# ATmega4809 device description
Architecture: AVR8X; Family: AVR MEGA
Registers are 8-bit, read-write, no defined reset value unless marked. A register's access mark holds for its fields unless they carry their own. Offsets are from the block's base; [hi:lo] are bit positions; {n}, {i} and the like mark numbered series; 'fields as' and 'values as' point back to an identical list.

## FUSE — Fuses
Instances: FUSE 0x1280
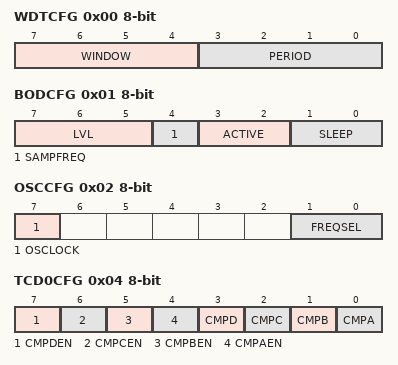
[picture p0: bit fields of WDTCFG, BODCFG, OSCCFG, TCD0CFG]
0x00 WDTCFG — Watchdog Configuration
  [7:4] WINDOW — Watchdog Window Timeout Period
    0=OFF; 1=8CLK (8 cycles (8ms)); 2=16CLK (16 cycles (16ms)); 3=32CLK (32 cycles (32ms)); 4=64CLK (64 cycles (64ms)); 5=128CLK (128 cycles (0.128s)); 6=256CLK (256 cycles (0.256s)); 7=512CLK (512 cycles (0.512s)); 8=1KCLK (1K cycles (1.0s)); 9=2KCLK (2K cycles (2.0s)); 10=4KCLK (4K cycles (4.1s)); 11=8KCLK (8K cycles (8.2s))
  [3:0] PERIOD — Watchdog Timeout Period
    values as WINDOW
0x01 BODCFG — BOD Configuration
  [7:5] LVL — BOD Level
    0=BODLEVEL0 (1.8 V); 1=BODLEVEL1 (2.1 V); 2=BODLEVEL2 (2.6 V); 3=BODLEVEL3 (2.9 V); 4=BODLEVEL4 (3.3 V); 5=BODLEVEL5 (3.7 V); 6=BODLEVEL6 (4.0 V); 7=BODLEVEL7 (4.2 V)
  [4] SAMPFREQ — BOD Sample Frequency
    0=1KHZ (1kHz sampling frequency); 1=125HZ (125kHz sampling frequency)
  [3:2] ACTIVE — BOD Operation in Active Mode
    0=DIS (Disabled); 1=ENABLED; 2=SAMPLED; 3=ENWAKE (Enabled with wake-up halted until BOD is ready)
  [1:0] SLEEP — BOD Operation in Sleep Mode
    0=DIS (Disabled); 1=ENABLED; 2=SAMPLED
0x02 OSCCFG — Oscillator Configuration
  [7] OSCLOCK — Oscillator Lock
  [1:0] FREQSEL — Frequency Select
    1=16MHZ; 2=20MHZ
0x04 TCD0CFG — TCD0 Configuration
  [7] CMPDEN — Compare D Output Enable
  [6] CMPCEN — Compare C Output Enable
  [5] CMPBEN — Compare B Output Enable
  [4] CMPAEN — Compare A Output Enable
  [3] CMPD — Compare D Default Output Value
  [2] CMPC — Compare C Default Output Value
  [1] CMPB — Compare B Default Output Value
  [0] CMPA — Compare A Default Output Value
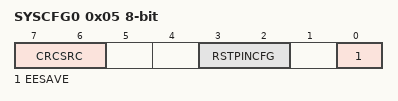
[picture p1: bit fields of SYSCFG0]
0x05 SYSCFG0 — System Configuration 0
  [7:6] CRCSRC — CRC Source
    0=FLASH (The CRC is performed on the entire Flash (boot, application code and application data section).); 1=BOOT (The CRC is performed on the boot section of Flash); 2=BOOTAPP (The CRC is performed on the boot and application code section of Flash); 3=NOCRC (Disable CRC.)
  [3:2] RSTPINCFG — Reset Pin Configuration
    0=GPIO (GPIO mode); 1=UPDI (UPDI mode); 2=RST (Reset mode); 3=PDIRST (PDI on PDI pad, reset on alternative reset pad)
  [0] EESAVE — EEPROM Save
0x06 SYSCFG1 — System Configuration 1
  [2:0] SUT — Startup Time
    0=0MS; 1=1MS; 2=2MS; 3=4MS; 4=8MS; 5=16MS; 6=32MS; 7=64MS
0x07 APPEND — Application Code Section End
0x08 BOOTEND — Boot Section End

## GPIO — General Purpose IO
Instances: GPIO 0x001C
{0x0+i} GPIOR{i} (i=0..3) — General Purpose IO Register {i}

## LOCKBIT
Instances: LOCKBIT 0x128A
0x00 LOCKBIT — Lock Bits
  [7:0] LB
    58=RWLOCK (Read and write lock); 197=NOLOCK (No locks)

## NVMBIST — BIST in the NVMCTRL module
Instances: NVMBIST 0x0C0
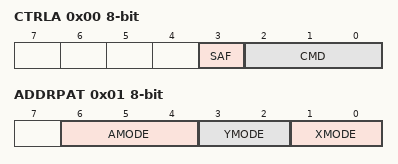
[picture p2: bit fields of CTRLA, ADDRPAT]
0x00 CTRLA — Control A
  [3] SAF — Stop at fault
  [2:0] CMD wo — Command
    0=NOCMD (No effect); 1=START (Start BIST testing); 2=RESTART (Re-start BIST testing); 3=BREAK (Stop BIST and go to BREAK state)
0x01 ADDRPAT — Address pattern
  [6:4] AMODE — Address mode
    0=NORMAL (No special address pattern); 4=COMPLEMENT (Post complement address)
  [3:2] YMODE — Y address mode
    0=STATIC (Y static); 1=CARRY (Carry/borrow from X); 2=INC (Y increment each cycle); 3=DEC (Y decrement each cycle)
  [1:0] XMODE — X address mode
    0=STATIC (X static); 1=CARRY (Carry/borrow from Y); 2=INC (X increment each cycle); 3=DEC (X decrement each cycle)
0x02 DATAPAT — Data pattern
  [1:0] PATTERN — Data check pattern
    0=ZEROES (All flash programmed); 1=CHECK (Physical checkerboard in flash); 2=INVCHECK (Inverse physical checkerboard in flash); 3=ONES (All flash unprogrammed)
0x03 STATUS ro
  [3:0] STATE — FSM State
    0=IDLE (Reset state); 1=BREAK (Break command used); 4=FAILED0 (Test failed, data from last address); 5=FAILED1 (Test failed, data from address-1); 6=FAILED2 (Test failed, data from address-2); 7=SUCCESS (Test success); 8=START0 (Startup, fetching first data); 9=START1 (Startup, fetching second data); 10=RESTART0 (Re-start from BREAK or FAILED2); 11=RESTART1 (Re-start from FAILED1); 12=RUNNING (Test running); 14=FINISH0 (Check last word); 15=FINISH1 (Count faults in last word)
0x04 CNT 16-bit
  [10:0] CNT — Faults counter
0x06 END 32-bit
  [23:0] END
